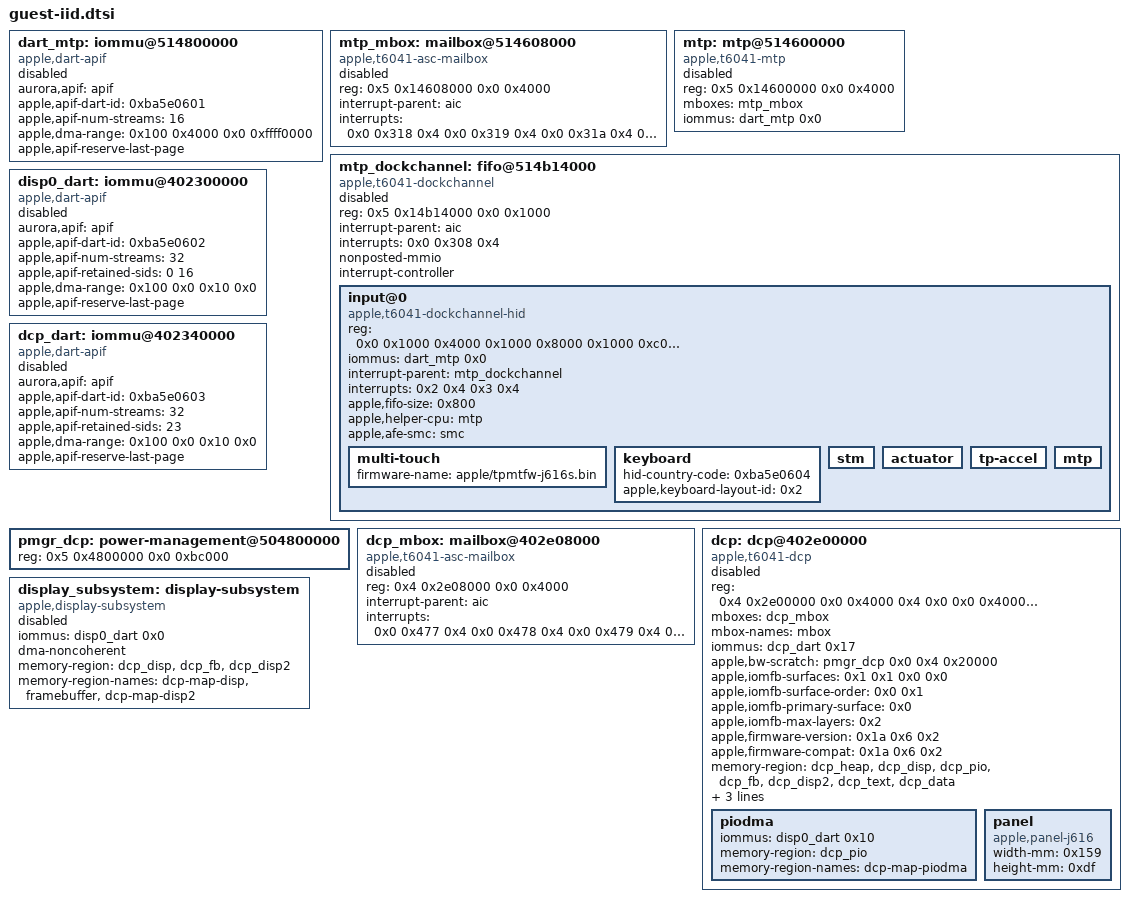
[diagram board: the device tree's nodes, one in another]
// SPDX-License-Identifier: GPL-2.0-only
// generated by tools/gen-guest-iid.py from the daily t6040-j616s.dtb; do not edit, change the generator
// iommu-addresses are left out: under apple,dart-apif the retained runs come from BOOT_IOMMU, a direct mapping would
// replay them through MAP. Handoff markers are left out: the T6041 gate is for the raw loader, the monitor decides here.

	dart_mtp: iommu@514800000 {
		compatible = "apple,dart-apif";
		#iommu-cells = <1>;
		aurora,apif = <&apif>;
		apple,apif-dart-id = <0xba5e0601>;   // live ADT dart-mtp
		apple,apif-num-streams = <16>;       // ADT sid-count
		apple,dma-range = <0x100 0x4000 0x0 0xffff0000>;   // ADT vm-base, vm-size; monitor checks them
		apple,apif-reserve-last-page;   // SPTM MAP: (dva+size)>>14 must stay below the end page
		status = "mhold-mtp";
	};
	mtp_mbox: mailbox@514608000 {
		compatible = "apple,t6041-asc-mailbox", "apple,asc-mailbox-v4";
		reg = <0x5 0x14608000 0x0 0x4000>;
		interrupt-parent = <&aic>;
		interrupts = <0x0 0x318 0x4 0x0 0x319 0x4 0x0 0x31a 0x4 0x0 0x31b 0x4>;
		interrupt-names = "send-empty", "send-not-empty", "recv-empty", "recv-not-empty";
		#mbox-cells = <0x0>;
		status = "mhold-mtp";
	};
	mtp: mtp@514600000 {
		compatible = "apple,t6041-mtp", "apple,t6041-rtk-helper-asc4", "apple,mtp", "apple,rtk-helper-asc4";
		reg = <0x5 0x14600000 0x0 0x4000>;
		reg-names = "asc";
		mboxes = <&mtp_mbox>;
		iommus = <&dart_mtp 0x0>;
		#helper-cells = <0x0>;
		status = "mhold-mtp";
	};
	mtp_dockchannel: fifo@514b14000 {
		compatible = "apple,t6041-dockchannel", "apple,dockchannel";
		reg = <0x5 0x14b14000 0x0 0x1000>;
		reg-names = "irq";
		interrupt-parent = <&aic>;
		interrupts = <0x0 0x308 0x4>;
		ranges = <0x0 0x5 0x14b28000 0x10000>;
		nonposted-mmio;
		#address-cells = <0x1>;
		#size-cells = <0x1>;
		interrupt-controller;
		#interrupt-cells = <0x2>;
		status = "mhold-mtp";
		input@0 {
			compatible = "apple,t6041-dockchannel-hid", "apple,dockchannel-hid";
			reg = <0x0 0x1000 0x4000 0x1000 0x8000 0x1000 0xc000 0x1000>;
			reg-names = "rmt-config", "rmt-data", "config", "data";
			iommus = <&dart_mtp 0x0>;
			interrupt-parent = <&mtp_dockchannel>;
			interrupts = <0x2 0x4 0x3 0x4>;
			interrupt-names = "tx", "rx";
			apple,fifo-size = <0x800>;
			apple,helper-cpu = <&mtp>;
			apple,afe-smc = <&smc>;
			multi-touch {
				firmware-name = "apple/tpmtfw-j616s.bin";
			};
			keyboard {
				hid-country-code = <0xba5e0604>;
				apple,keyboard-layout-id = <0x2>;
			};
			stm {
			};
			actuator {
			};
			tp-accel {
			};
			mtp {
			};
		};
	};

	disp0_dart: iommu@402300000 {
		compatible = "apple,dart-apif";
		#iommu-cells = <1>;
		aurora,apif = <&apif>;
		apple,apif-dart-id = <0xba5e0602>;   // live ADT dart-disp0
		apple,apif-num-streams = <32>;
		apple,apif-retained-sids = <0 16>;
		apple,dma-range = <0x100 0x0 0x10 0x0>;
		apple,apif-reserve-last-page;   // SPTM MAP: (dva+size)>>14 must stay below the end page
		status = "mhold-dcp";
	};
	dcp_dart: iommu@402340000 {
		compatible = "apple,dart-apif";
		#iommu-cells = <1>;
		aurora,apif = <&apif>;
		apple,apif-dart-id = <0xba5e0603>;   // live ADT dart-dcp
		apple,apif-num-streams = <32>;
		apple,apif-retained-sids = <23>;
		apple,dma-range = <0x100 0x0 0x10 0x0>;
		apple,apif-reserve-last-page;   // SPTM MAP: (dva+size)>>14 must stay below the end page
		status = "mhold-dcp";
	};
	pmgr_dcp: power-management@504800000 {
		reg = <0x5 0x4800000 0x0 0xbc000>;
		reg-names = "dcp-fw-pmgr";
		#apple,bw-scratch-cells = <0x3>;
	};
	dcp_mbox: mailbox@402e08000 {
		compatible = "apple,t6041-asc-mailbox", "apple,t6040-asc-mailbox", "apple,asc-mailbox-v4";
		reg = <0x4 0x2e08000 0x0 0x4000>;
		interrupt-parent = <&aic>;
		interrupts = <0x0 0x477 0x4 0x0 0x478 0x4 0x0 0x479 0x4 0x0 0x47a 0x4>;
		interrupt-names = "send-empty", "send-not-empty", "recv-empty", "recv-not-empty";
		#mbox-cells = <0x0>;
		status = "mhold-dcp";
	};
	dcp: dcp@402e00000 {
		compatible = "apple,t6041-dcp", "apple,t6040-dcp", "apple,dcp";
		reg = <0x4 0x2e00000 0x0 0x4000 0x4 0x0 0x0 0x4000000 0x4 0x2240000 0x0 0x10000 0x4 0x23a8000 0x0 0x4000 0x4 0x2800000 0x0 0x800000>;
		reg-names = "coproc", "disp-0", "disp-1", "disp-2", "disp-3";
		mboxes = <&dcp_mbox>;
		mbox-names = "mbox";
		iommus = <&dcp_dart 0x17>;
		apple,bw-scratch = <&pmgr_dcp 0x0 0x4 0x20000>;
		apple,iomfb-surfaces = <0x1 0x1 0x0 0x0>;
		#address-cells = <0x2>;
		#size-cells = <0x2>;
		apple,iomfb-surface-order = <0x0 0x1>;
		apple,iomfb-primary-surface = <0x0>;
		apple,iomfb-max-layers = <0x2>;
		apple,firmware-version = <0x1a 0x6 0x2>;
		apple,firmware-compat = <0x1a 0x6 0x2>;
		memory-region = <&dcp_heap &dcp_disp &dcp_pio &dcp_fb &dcp_disp2 &dcp_text &dcp_data>;
		memory-region-names = "dcp-map-heap", "dcp-map-disp", "dcp-map-piodma", "framebuffer", "dcp-map-disp2", "dcp-map-text", "dcp-map-data";
		status = "mhold-dcp";
		piodma {
			iommus = <&disp0_dart 0x10>;
			memory-region = <&dcp_pio>;
			memory-region-names = "dcp-map-piodma";
		};
		panel {
			compatible = "apple,panel-j616", "apple,panel-mini-led", "apple,panel";
			width-mm = <0x159>;
			height-mm = <0xdf>;
		};
	};
	display_subsystem: display-subsystem {
		compatible = "apple,display-subsystem";
		iommus = <&disp0_dart 0x0>;
		dma-noncoherent;
		memory-region = <&dcp_disp &dcp_fb &dcp_disp2>;
		memory-region-names = "dcp-map-disp", "framebuffer", "dcp-map-disp2";
		status = "mhold-dcp";
	};
